# ATSAMC21J17AU register map
Vendor: Microchip Technology Inc.; Series: SAMC21; File version: C
CPU: CM0+ r0p1, little endian, MPU, no FPU, VTOR, 2 interrupt priority bits, 31 interrupts
Registers are 32-bit, read-write, reset 0x0 unless marked. A register's access mark holds for its fields unless they carry their own. Offsets are from the block's base; [hi:lo] are bit positions; {n}, {i} and the like mark numbered series; 'fields as' and 'values as' point back to an identical list.

## PM — Power Manager
Base 0x40000400; register names take the prefix PM_
0x01 SLEEPCFG 8-bit — Sleep Configuration
  [2:0] SLEEPMODE
    0=IDLE0 (CPU clock is OFF); 1=IDLE1 (AHB clock is OFF); 2=IDLE2 (APB clock are OFF); 4=STANDBY (All Clocks are OFF)
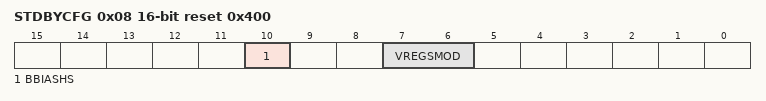
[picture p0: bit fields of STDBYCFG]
0x08 STDBYCFG 16-bit reset 0x400 — Standby Configuration
  [10] BBIASHS — Back Bias for HMCRAMCHS
  [7:6] VREGSMOD — Voltage Regulator Standby mode
    0=AUTO (Automatic mode); 1=PERFORMANCE (Performance oriented); 2=LP (Low Power oriented)

## PORT — Port Module
Base 0x41000000; register names take the prefix PORT_
Same registers: PORT_IOBUS 0x60000000 (register names take the prefix PORT_IOBUS_)
{0x0+0x80*i} DIR{i} (i=0..1) — Data Direction
{0x4+0x80*i} DIRCLR{i} (i=0..1) — Data Direction Clear
{0x8+0x80*i} DIRSET{i} (i=0..1) — Data Direction Set
{0xC+0x80*i} DIRTGL{i} (i=0..1) — Data Direction Toggle
{0x10+0x80*i} OUT{i} (i=0..1) — Data Output Value
{0x14+0x80*i} OUTCLR{i} (i=0..1) — Data Output Value Clear
{0x18+0x80*i} OUTSET{i} (i=0..1) — Data Output Value Set
{0x1C+0x80*i} OUTTGL{i} (i=0..1) — Data Output Value Toggle
{0x20+0x80*i} IN{i} (i=0..1) ro — Data Input Value
{0x24+0x80*i} CTRL{i} (i=0..1) — Control
  [31:0] SAMPLING wo — Input Sampling Mode
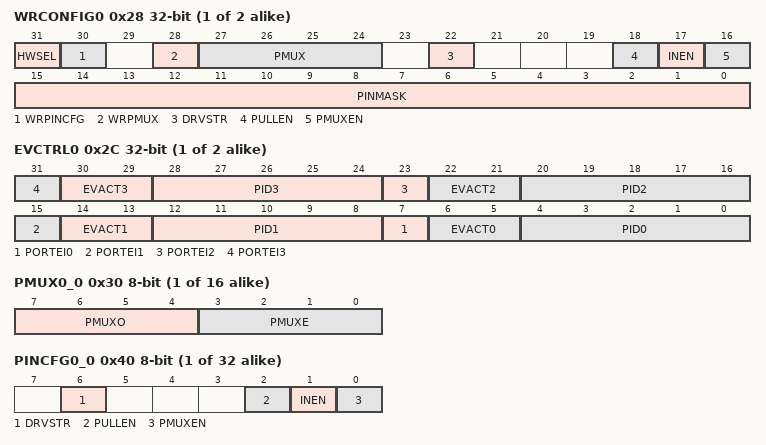
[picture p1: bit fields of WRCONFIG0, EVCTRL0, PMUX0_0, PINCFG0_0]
{0x28+0x80*i} WRCONFIG{i} (i=0..1) wo — Write Configuration
  [31] HWSEL — Half-Word Select
  [30] WRPINCFG — Write PINCFG Registers
  [28] WRPMUX — Write PMUX Registers
  [27:24] PMUX — Peripheral Multiplexing Template
  [22] DRVSTR — Output Driver Strength Selection
  [18] PULLEN — Pull Enable
  [17] INEN — Input Enable
  [16] PMUXEN — Select Peripheral Multiplexer
  [15:0] PINMASK — Pin Mask for Multiple Pin Configuration
{0x2C+0x80*i} EVCTRL{i} (i=0..1) — Event Input Control
  [8n+7] PORTEI{n} (n=0..3) — Port Event Enable Input {n}
  [30:29] EVACT3 — Port Event Action 3
  [8n+4:8n] PID{n} (n=0..3) — Port Event Pin Identifier {n}
  [22:21] EVACT2 — Port Event Action 2
  [14:13] EVACT1 — Port Event Action 1
  [6:5] EVACT0 — Port Event Action 0
    0=OUT (Event output to pin); 1=SET (Set output register of pin on event); 2=CLR (Clear output register of pin on event); 3=TGL (Toggle output register of pin on event)
{0x30+i} PMUX0_{i} (i=0..15) 8-bit — Peripheral Multiplexing n - Group 0
  [7:4] PMUXO — Peripheral Multiplexing for Odd-Numbered Pin
  [3:0] PMUXE — Peripheral Multiplexing for Even-Numbered Pin
{0x40+i} PINCFG0_{i} (i=0..31) 8-bit — Pin Configuration n - Group 0
  [6] DRVSTR wo — Output Driver Strength Selection
  [2] PULLEN — Pull Enable
  [1] INEN — Input Enable
  [0] PMUXEN — Select Peripheral Multiplexer
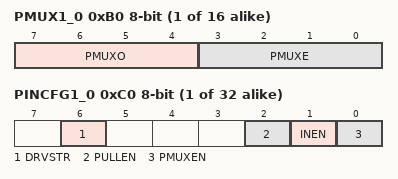
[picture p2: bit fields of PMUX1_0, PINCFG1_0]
{0xB0+i} PMUX1_{i} (i=0..15) 8-bit — Peripheral Multiplexing n - Group 1
  fields as PMUX0_0
{0xC0+i} PINCFG1_{i} (i=0..31) 8-bit — Pin Configuration n - Group 1
  fields as PINCFG0_0

## RSTC — Reset Controller
Base 0x40000C00; register names take the prefix RSTC_
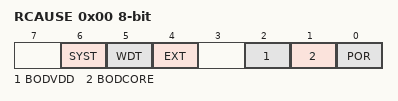
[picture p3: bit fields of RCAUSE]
0x00 RCAUSE 8-bit ro — Reset Cause
  [6] SYST — System Reset Request
  [5] WDT — Watchdog Reset
  [4] EXT — External Reset
  [2] BODVDD — Brown Out VDD Detector Reset
  [1] BODCORE — Brown Out CORE Detector Reset
  [0] POR — Power On Reset

## SDADC — Sigma-Delta Analog Digital Converter
Base 0x42004C00; register names take the prefix SDADC_
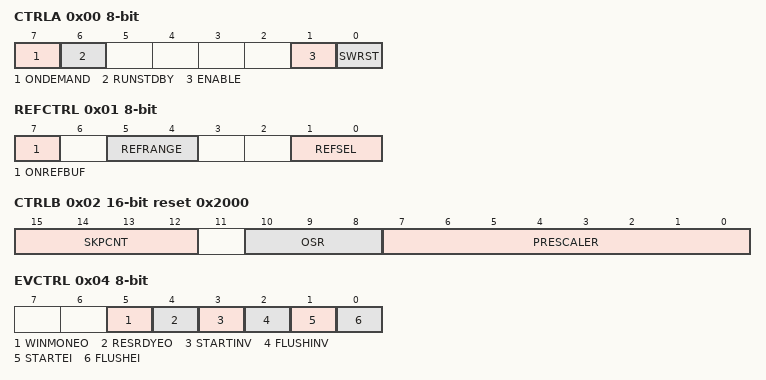
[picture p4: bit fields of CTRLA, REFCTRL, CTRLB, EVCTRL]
0x00 CTRLA 8-bit — Control A
  [7] ONDEMAND — On Demand Control
  [6] RUNSTDBY — Run during Standby
  [1] ENABLE
  [0] SWRST — Software Reset
0x01 REFCTRL 8-bit — Reference Control
  [7] ONREFBUF — Reference Buffer
  [5:4] REFRANGE — Reference Range
  [1:0] REFSEL — Reference Selection
    0=INTREF (Internal Bandgap Reference); 1=AREFB (External Reference); 2=DAC (Internal DAC Output); 3=INTVCC (VDDANA)
0x02 CTRLB 16-bit reset 0x2000 — Control B
  [15:12] SKPCNT — Skip Sample Count
  [10:8] OSR — Over Sampling Ratio
  [7:0] PRESCALER — Prescaler Configuration
0x04 EVCTRL 8-bit — Event Control
  [5] WINMONEO — Window Monitor Event Out
  [4] RESRDYEO — Result Ready Event Out
  [3] STARTINV — Satrt Event Invert Enable
  [2] FLUSHINV — Flush Event Invert Enable
  [1] STARTEI — Start Conversion Event Input Enable
  [0] FLUSHEI — Flush Event Input Enable
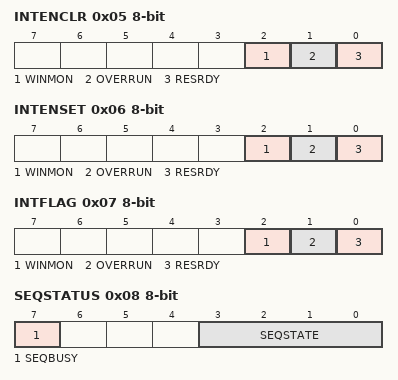
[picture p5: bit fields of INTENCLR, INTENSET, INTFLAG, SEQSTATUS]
0x05 INTENCLR 8-bit — Interrupt Enable Clear
  [2] WINMON — Window Monitor Interrupt Disable
  [1] OVERRUN — Overrun Interrupt Disable
  [0] RESRDY — Result Ready Interrupt Disable
0x06 INTENSET 8-bit — Interrupt Enable Set
  [2] WINMON — Window Monitor Interrupt Enable
  [1] OVERRUN — Overrun Interrupt Enable
  [0] RESRDY — Result Ready Interrupt Enable
0x07 INTFLAG 8-bit — Interrupt Flag Status and Clear
  [2] WINMON — Window Monitor Interrupt Flag
  [1] OVERRUN — Overrun Interrupt Flag
  [0] RESRDY — Result Ready Interrupt Flag
0x08 SEQSTATUS 8-bit ro — Sequence Status
  [7] SEQBUSY — Sequence Busy
  [3:0] SEQSTATE — Sequence State
0x09 INPUTCTRL 8-bit — Input Control
  [3:0] MUXSEL — SDADC Input Selection
    0=AIN0 (SDADC AIN0 Pin); 1=AIN1 (SDADC AIN1 Pin); 2=AIN2 (SDADC AIN2 Pin)
0x0A CTRLC 8-bit — Control C
  [0] FREERUN — Free Running Mode
0x0B WINCTRL 8-bit — Window Monitor Control
  [2:0] WINMODE — Window Monitor Mode
0x0C WINLT — Window Monitor Lower Threshold
  [23:0] WINLT — Window Lower Threshold
0x10 WINUT — Window Monitor Upper Threshold
  [23:0] WINUT — Window Upper Threshold
0x14 OFFSETCORR — Offset Correction
  [23:0] OFFSETCORR — Offset Correction Value
0x18 GAINCORR 16-bit reset 0x1 — Gain Correction
  [13:0] GAINCORR — Gain Correction Value
0x1A SHIFTCORR 8-bit — Shift Correction
  [3:0] SHIFTCORR — Shift Correction Value
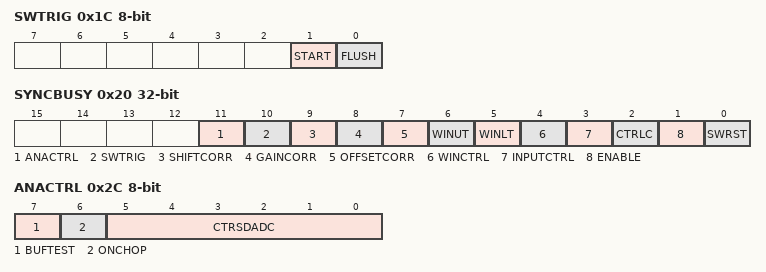
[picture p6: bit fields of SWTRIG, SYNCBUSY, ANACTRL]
0x1C SWTRIG 8-bit — Software Trigger
  [1] START — Start SDADC Conversion
  [0] FLUSH — SDADC Flush
0x20 SYNCBUSY ro — Synchronization Busy
  [11] ANACTRL — ANACTRL Synchronization Busy
  [10] SWTRIG — SWTRG Synchronization Busy
  [9] SHIFTCORR — SHIFTCORR Synchronization Busy
  [8] GAINCORR — GAINCORR Synchronization Busy
  [7] OFFSETCORR — OFFSETCTRL Synchronization Busy
  [6] WINUT — WINUT Synchronization Busy
  [5] WINLT — WINLT Synchronization Busy
  [4] WINCTRL — WINCTRL Synchronization Busy
  [3] INPUTCTRL — INPUTCTRL Synchronization Busy
  [2] CTRLC — CTRLC Synchronization Busy
  [1] ENABLE — ENABLE Synchronization Busy
  [0] SWRST — SWRST Synchronization Busy
0x24 RESULT ro
  [23:0] RESULT — Result Value
0x28 SEQCTRL 8-bit — Sequence Control
  [2:0] SEQEN — Enable Positive Input in the Sequence
0x2C ANACTRL 8-bit — Analog Control
  [7] BUFTEST
  [6] ONCHOP — Chopper
  [5:0] CTRSDADC — SDADC Control
0x2E DBGCTRL 8-bit — Debug Control
  [0] DBGRUN — Debug Run

## Notices in the file
Copyright (c) 2018 Microchip Technology Inc.
SPDX-License-Identifier: Apache-2.0
Licensed under the Apache License, Version 2.0 (the "License");
you may not use this file except in compliance with the License.
You may obtain a copy of the License at
http://www.apache.org/licenses/LICENSE-2.0
Unless required by applicable law or agreed to in writing, software
distributed under the License is distributed on an "AS IS" BASIS,
WITHOUT WARRANTIES OR CONDITIONS OF ANY KIND, either express or implied.
See the License for the specific language governing permissions and
limitations under the License.
